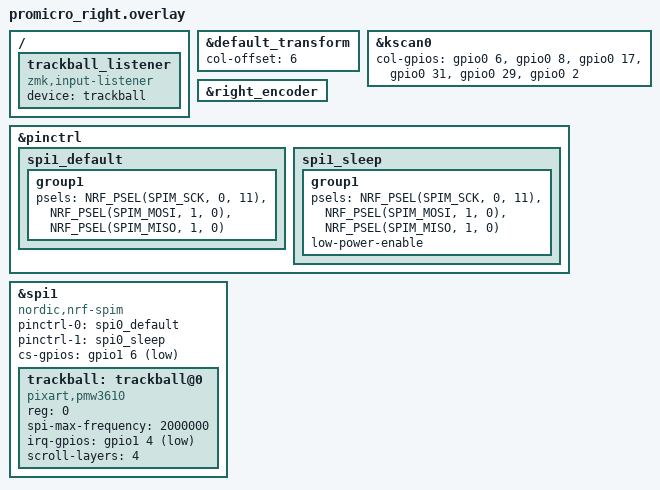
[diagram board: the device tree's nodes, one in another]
// promicro_right.overlay

#include "promicro.dtsi"

&default_transform {
    col-offset = <6>;
};

&kscan0 {
    col-gpios
        = <&gpio0 6 GPIO_ACTIVE_HIGH> 
        , <&gpio0 8 GPIO_ACTIVE_HIGH>
        , <&gpio0 17 GPIO_ACTIVE_HIGH>
        , <&gpio0 31 GPIO_ACTIVE_HIGH>
        , <&gpio0 29 GPIO_ACTIVE_HIGH>
        , <&gpio0 2 GPIO_ACTIVE_HIGH>
        ;
};

&right_encoder {
status = "okay";

};

&pinctrl {
    spi1_default: spi1_default {
        group1 {
            psels = <NRF_PSEL(SPIM_SCK, 0, 11)>,
                <NRF_PSEL(SPIM_MOSI, 1, 0)>,
                <NRF_PSEL(SPIM_MISO, 1, 0)>;
        };
    };

    spi1_sleep: spi1_sleep {
        group1 {
            psels = <NRF_PSEL(SPIM_SCK, 0, 11)>,
                <NRF_PSEL(SPIM_MOSI, 1, 0)>,
                <NRF_PSEL(SPIM_MISO, 1, 0)>;
            low-power-enable;
        };
    };
};

&spi1 {
    status = "okay";
    compatible = "nordic,nrf-spim";
    pinctrl-0 = <&spi0_default>;
    pinctrl-1 = <&spi0_sleep>;
    pinctrl-names = "default", "sleep";
    cs-gpios = <&gpio1 6 GPIO_ACTIVE_LOW>;

  trackball: trackball@0 {
      status = "okay";
      compatible = "pixart,pmw3610";
      reg = <0>;
      spi-max-frequency = <2000000>;
      irq-gpios = <&gpio1 4 (GPIO_ACTIVE_LOW | GPIO_PULL_UP)>;
      scroll-layers = <4>;
  };
};

/ {
  trackball_listener {
    compatible = "zmk,input-listener";
    device = <&trackball>;
  };
};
